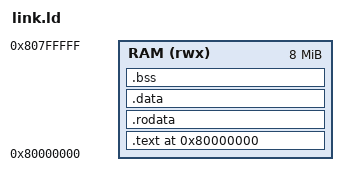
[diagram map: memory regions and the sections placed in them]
/*
 * Link script for the QEMU 'virt' RV32 machine.
 *
 * RAM base is 0x8000_0000. The image is position-dependent and linked to run
 * in place from there. .text.init (the reset entry) is kept first so it lands
 * exactly at the RAM base where QEMU jumps.
 */

OUTPUT_ARCH("riscv")
OUTPUT_FORMAT("elf32-littleriscv")
ENTRY(_start)

MEMORY
{
    RAM (rwx) : ORIGIN = 0x80000000, LENGTH = 8M
}

STACK_SIZE = 0x4000;

SECTIONS
{
    . = ORIGIN(RAM);

    .text : {
        KEEP(*(.text.init))
        *(.text .text.*)
    } > RAM

    .rodata : {
        *(.rodata .rodata.*)
        *(.srodata .srodata.*)
    } > RAM

    .data : {
        *(.data .data.*)
        *(.sdata .sdata.*)
    } > RAM

    .bss (NOLOAD) : {
        . = ALIGN(4);
        _bss_start = .;
        *(.sbss .sbss.*)
        *(.bss .bss.*)
        *(COMMON)
        . = ALIGN(4);
        _bss_end = .;
    } > RAM

    . = ALIGN(16);
    . = . + STACK_SIZE;
    _stack_top = .;

    /DISCARD/ : {
        *(.comment)
        *(.note .note.*)
        *(.eh_frame)
    }
}
